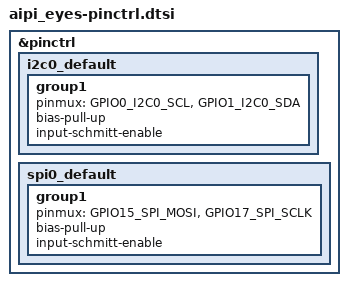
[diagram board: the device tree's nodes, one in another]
/*
 * Copyright (c) 2026 Panoramix Labs
 *
 * SPDX-License-Identifier: Apache-2.0
 */

&pinctrl {
	/* "J9" connector (1:3V3, 2:SCL, 3:SDA, 4:GND), at the top, shared with
	 * the touch controller, the DVP camera connector and, on the S1, the
	 * audio codec
	 */
	i2c0_default: i2c0_default {
		group1 {
			pinmux = <GPIO0_I2C0_SCL>,
				 <GPIO1_I2C0_SDA>;
			bias-pull-up;
			input-schmitt-enable;
		};
	};

	/* "SPI Touch Screen", "CON1" connector */
	spi0_default: spi0_default {
		group1 {
			pinmux = <GPIO15_SPI_MOSI>,
				 <GPIO17_SPI_SCLK>;
			bias-pull-up;
			input-schmitt-enable;
		};
	};
};
